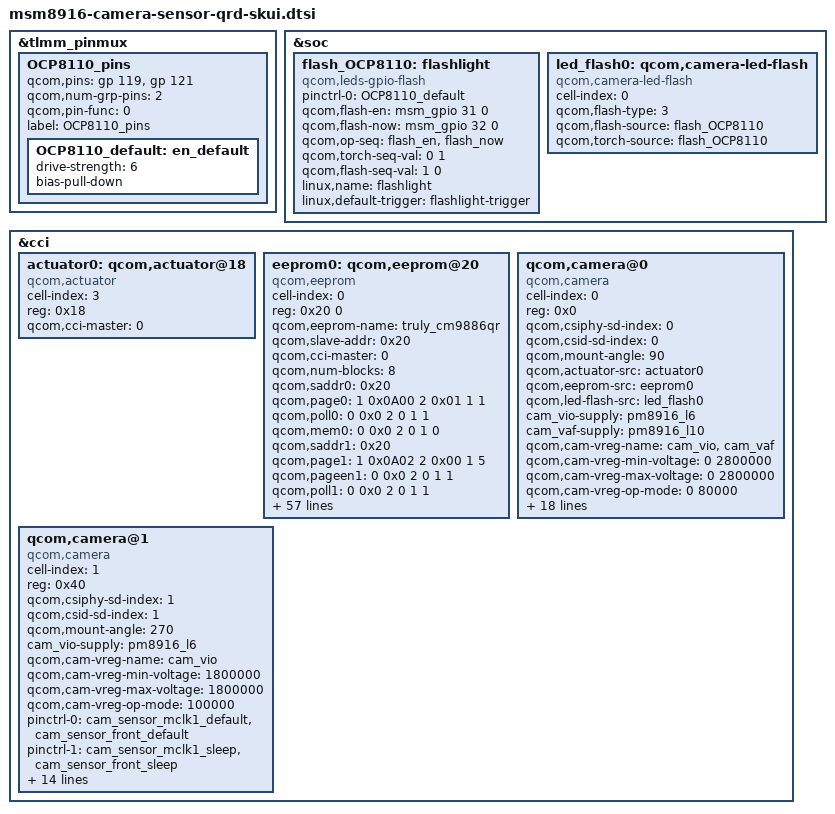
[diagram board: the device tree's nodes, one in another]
/*
 * Copyright (c) 2014, The Linux Foundation. All rights reserved.
 *
 * This program is free software; you can redistribute it and/or modify
 * it under the terms of the GNU General Public License version 2 and
 * only version 2 as published by the Free Software Foundation.
 *
 * This program is distributed in the hope that it will be useful,
 * but WITHOUT ANY WARRANTY; without even the implied warranty of
 * MERCHANTABILITY or FITNESS FOR A PARTICULAR PURPOSE.  See the
 * GNU General Public License for more details.
 */

&tlmm_pinmux {
	OCP8110_pins {
		qcom,pins = <&gp 119>, <&gp 121>;
		qcom,num-grp-pins = <2>;
		qcom,pin-func = <0>;
		label = "OCP8110_pins";
		OCP8110_default: en_default {
			  drive-strength = <6>;
			  bias-pull-down;
		};
	};
};

&soc {
	flash_OCP8110:flashlight {
		compatible = "qcom,leds-gpio-flash";
		status = "okay";
		pinctrl-names = "flash_default";
		pinctrl-0 = <&OCP8110_default>;
		qcom,flash-en = <&msm_gpio 31 0>;
		qcom,flash-now = <&msm_gpio 32 0>;
		qcom,op-seq = "flash_en", "flash_now";
		qcom,torch-seq-val = <0 1>;
		qcom,flash-seq-val = <1 0>;
		linux,name = "flashlight";
		linux,default-trigger = "flashlight-trigger";
	};

	led_flash0: qcom,camera-led-flash {
		cell-index = <0>;
		compatible = "qcom,camera-led-flash";
		qcom,flash-type = <3>;
		qcom,flash-source = <&flash_OCP8110>;
		qcom,torch-source = <&flash_OCP8110>;
	};
};

&cci {

	actuator0: qcom,actuator@18 {
		cell-index = <3>;
		reg = <0x18>;
		compatible = "qcom,actuator";
		qcom,cci-master = <0>;
	};

	eeprom0: qcom,eeprom@20 {
		cell-index = <0>;
		reg = <0x20 0>;
		qcom,eeprom-name = "truly_cm9886qr";
		compatible = "qcom,eeprom";
		qcom,slave-addr = <0x20>;
		qcom,cci-master = <0>;
		qcom,num-blocks = <8>;

                qcom,saddr0 = <0x20>;
		qcom,page0 = <1 0x0A00 2 0x01 1 1>;
		qcom,poll0 = <0 0x0 2 0 1 1>;
		qcom,mem0 = <0 0x0 2 0 1 0>;

		qcom,saddr1 = <0x20>;
		qcom,page1 = <1 0x0A02 2 0x00 1 5>;
		qcom,pageen1 = <0 0x0 2 0 1 1>;
		qcom,poll1 = <0 0x0 2 0 1 1>;
		qcom,mem1 = <64 0x0A04 2 0 1 0>;


		qcom,saddr2 = <0x20>;
		qcom,page2 = <1 0x0A00 2 0x01 1 1>;
		qcom,poll2 = <0 0x0 2 0 1 1>;
		qcom,mem2 = <0 0x0 2 0 1 0>;

		qcom,saddr3 = <0x20>;
		qcom,page3  = <1 0x0A02 2 0x01 1 5>;
		qcom,pageen3 = <0 0x0 2 0 1 1>;
		qcom,poll3 = <0 0x0 2 0 1 1>;
		qcom,mem3 = <64 0x0A04 2 0 1 0>;

		qcom,saddr4 = <0x20>;
		qcom,page4 = <1 0x0A00 2 0x01 1 1>;
		qcom,poll4 = <0 0x0 2 0 1 1>;
		qcom,mem4 = <0 0x0 2 0 1 0>;

		qcom,saddr5 = <0x20>;
		qcom,page5  = <1 0x0A02 2 0x02 1 5>;
		qcom,pageen5 = <0 0x0 2 0 1 1>;
		qcom,poll5 = <0 0x0 2 0 1 1>;
		qcom,mem5 = <64 0x0A04 2 0 1 0>;


		qcom,saddr6 = <0x20>;
		qcom,page6 = <1 0x0A00 2 0x01 1 1>;
		qcom,poll6 = <0 0x0 2 0 1 1>;
		qcom,mem6 = <0 0x0 2 0 1 0>;

		qcom,saddr7 = <0x20>;
		qcom,page7  = <1 0x0A02 2 0x03 1 5>;
		qcom,pageen7 = <0 0x0 2 0 1 1>;
		qcom,poll7 = <0 0x0 2 0 1 1>;
		qcom,mem7 = <64 0x0A04 2 0 1 0>;

		cam_vio-supply = <&pm8916_l6>;
		cam_vaf-supply = <&pm8916_l10>;
		qcom,cam-vreg-name = "cam_vio","cam_vaf";
		qcom,cam-vreg-min-voltage = <0 2800000>;
		qcom,cam-vreg-max-voltage = <0 2800000>;
		qcom,cam-vreg-op-mode = <0 80000>;
		pinctrl-names = "cam_default", "cam_suspend";
		pinctrl-0 = <&cam_sensor_mclk0_default &cam_sensor_rear_default>;
		pinctrl-1 = <&cam_sensor_mclk0_sleep &cam_sensor_rear_sleep>;
		gpios = <&msm_gpio 26 0>,
			<&msm_gpio 35 0>,
			<&msm_gpio 113 0>,
                        <&msm_gpio 114 0>;
		qcom,gpio-reset = <1>;
		qcom,gpio-vdig = <2>;
		qcom,gpio-vana = <3>;
		qcom,gpio-req-tbl-num = <0 1 2 3>;
		qcom,gpio-req-tbl-flags = <1 0 0 0>;
		qcom,gpio-req-tbl-label = "CAMIF_MCLK",
			"CAM_RESET1",
			"CAM_VDIG",
			"CAM_VANA";

		qcom,cam-power-seq-type = "sensor_vreg",
                  "sensor_vreg","sensor_gpio",
		  "sensor_gpio", "sensor_gpio" ,
                  "sensor_clk";

		qcom,cam-power-seq-val = "cam_vio",
                  "cam_vaf","sensor_gpio_vdig",
		  "sensor_gpio_reset","sensor_gpio_vana",
                  "sensor_cam_mclk";
		qcom,cam-power-seq-cfg-val = <1 1 1 1 1 23880000>;
		qcom,cam-power-seq-delay = <5 5 5 5 5 5>;

		clocks = <&clock_gcc clk_mclk0_clk_src>,
			<&clock_gcc clk_gcc_camss_mclk0_clk>;
		clock-names = "cam_src_clk", "cam_clk";
	};

	qcom,camera@0 {
		cell-index = <0>;
		compatible = "qcom,camera";
		reg = <0x0>;
		qcom,csiphy-sd-index = <0>;
		qcom,csid-sd-index = <0>;
		qcom,mount-angle = <90>;
		qcom,actuator-src = <&actuator0>;
		qcom,eeprom-src = <&eeprom0>;
		qcom,led-flash-src = <&led_flash0>;
		cam_vio-supply = <&pm8916_l6>;
		cam_vaf-supply = <&pm8916_l10>;
		qcom,cam-vreg-name = "cam_vio","cam_vaf";
		qcom,cam-vreg-min-voltage = <0 2800000>;
		qcom,cam-vreg-max-voltage = <0 2800000>;
		qcom,cam-vreg-op-mode = <0 80000>;
		pinctrl-names = "cam_default", "cam_suspend";
		pinctrl-0 = <&cam_sensor_mclk0_default &cam_sensor_rear_default>;
		pinctrl-1 = <&cam_sensor_mclk0_sleep &cam_sensor_rear_sleep>;
		gpios = <&msm_gpio 26 0>,
			<&msm_gpio 35 0>,
			<&msm_gpio 113 0>,
			<&msm_gpio 114 0>;
		qcom,gpio-reset = <1>;
		qcom,gpio-vdig = <2>;
		qcom,gpio-vana = <3>;
		qcom,gpio-req-tbl-num = <0 1 2 3>;
		qcom,gpio-req-tbl-flags = <1 0 0 0>;
		qcom,gpio-req-tbl-label = "CAMIF_MCLK",
			"CAM_RESET1",			
                        "CAM_VDIG",
			"CAM_VANA";
		qcom,sensor-position = <0>;
		qcom,sensor-mode = <0>;
		qcom,cci-master = <0>;
		status = "ok";
		clocks = <&clock_gcc clk_mclk0_clk_src>,
				<&clock_gcc clk_gcc_camss_mclk0_clk>;
		clock-names = "cam_src_clk", "cam_clk";
	};
};

&cci {

	qcom,camera@1 {
		cell-index = <1>;
		compatible = "qcom,camera";
		reg = <0x40>;
		qcom,csiphy-sd-index = <1>;
		qcom,csid-sd-index = <1>;
		qcom,mount-angle = <270>;
		cam_vio-supply = <&pm8916_l6>;
		qcom,cam-vreg-name = "cam_vio";
		qcom,cam-vreg-min-voltage = <1800000>;
		qcom,cam-vreg-max-voltage = <1800000>;
		qcom,cam-vreg-op-mode = <100000>;
		pinctrl-names = "cam_default", "cam_suspend";
		pinctrl-0 = <&cam_sensor_mclk1_default &cam_sensor_front_default>;
		pinctrl-1 = <&cam_sensor_mclk1_sleep &cam_sensor_front_sleep>;
		gpios = <&msm_gpio 27 0>,
			<&msm_gpio 28 0>,
			<&msm_gpio 33 0>,
                        <&msm_gpio 79 0>,
                        <&msm_gpio 114 0>;
		qcom,gpio-reset = <1>;
		qcom,gpio-standby = <2>;
		qcom,gpio-vdig = <3>;
		qcom,gpio-vana = <4>;
		qcom,gpio-req-tbl-num = <0 1 2 3 4>;
		qcom,gpio-req-tbl-flags = <1 0 0 0 0>;
		qcom,gpio-req-tbl-label = "CAMIF_MCLK",
			"CAM_RESET",
			"CAM_STANDBY",
			"CAM_VDIG",
			"CAM_VANA";
		qcom,cci-master = <0>;
		qcom,mclk-23880000;
		status = "ok";
		clocks = <&clock_gcc clk_mclk1_clk_src>,
				<&clock_gcc clk_gcc_camss_mclk1_clk>;
		clock-names = "cam_src_clk", "cam_clk";
	};
};

